AUTOSAR XML (schema 4-2-2)
package /ComponentTypes
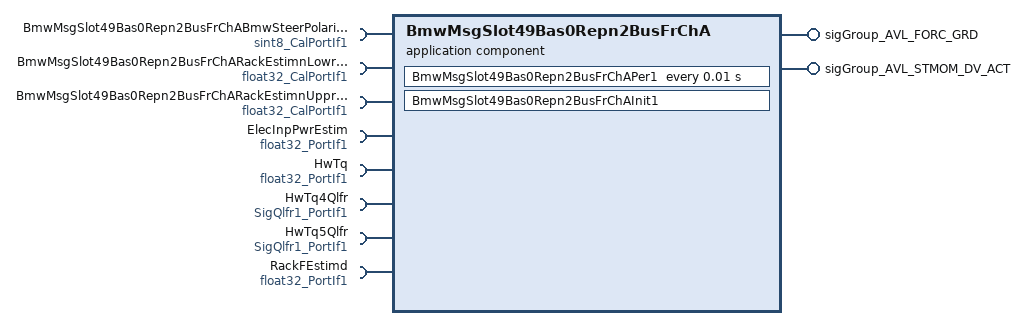
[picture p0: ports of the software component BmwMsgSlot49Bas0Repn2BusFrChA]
  application sw component type BmwMsgSlot49Bas0Repn2BusFrChA
    provide port sigGroup_AVL_FORC_GRD: nonqueued-sender-com-spec{data-element=sigGroup_AVL_FORC_GRD, uses-end-to-end-protection=true, init-value=fields=[AVL_FORC_GRD:0, AVL_PWR_EL_EPS_COOD:120, ALIV_AVL_FORC_GRD:15, CRC_AVL_FORC_GRD:0, QU_AVL_FORC_GRD:8, AVL_FORC_GRD_dummy_12_15:15]}, provided-interface=sigGroup_AVL_FORC_GRD
    provide port sigGroup_AVL_STMOM_DV_ACT: nonqueued-sender-com-spec{data-element=sigGroup_AVL_STMOM_DV_ACT, uses-end-to-end-protection=true, init-value=fields=[AVL_STMOM_DV_ACT:2000, ALIV_AVL_STMOM_DV_ACT:15, QU_AVL_STMOM_DV_ACT:8, CRC_AVL_STMOM_DV_ACT:0, AVL_STMOM_DV_ACT_dummy_12_15:15]}, provided-interface=sigGroup_AVL_STMOM_DV_ACT
    8 x require port:
      BmwMsgSlot49Bas0Repn2BusFrChABmwSteerPolarity: parameter-require-com-spec{init-value=-1, parameter=Val}, required-interface=sint8_CalPortIf1
      BmwMsgSlot49Bas0Repn2BusFrChARackEstimnLowrLim: parameter-require-com-spec{init-value=-25000, parameter=Val}, required-interface=float32_CalPortIf1
      BmwMsgSlot49Bas0Repn2BusFrChARackEstimnUpprLim: parameter-require-com-spec{init-value=25000, parameter=Val}, required-interface=float32_CalPortIf1
      ElecInpPwrEstim: nonqueued-receiver-com-spec{data-element=Val, filter=data-filter-type=ALWAYS, init-value=0}, required-interface=float32_PortIf1
      HwTq: nonqueued-receiver-com-spec{data-element=Val, filter=data-filter-type=ALWAYS, init-value=0}, required-interface=float32_PortIf1
      HwTq4Qlfr: nonqueued-receiver-com-spec{data-element=Val, filter=data-filter-type=ALWAYS, init-value=0}, required-interface=SigQlfr1_PortIf1
      HwTq5Qlfr: nonqueued-receiver-com-spec{data-element=Val, filter=data-filter-type=ALWAYS, init-value=0}, required-interface=SigQlfr1_PortIf1
      RackFEstimd: nonqueued-receiver-com-spec{data-element=Val, filter=data-filter-type=ALWAYS, init-value=0}, required-interface=float32_PortIf1
    behavior BmwMsgSlot49Bas0Repn2BusFrChA_InternalBehavior
      ar-typed-per-instance-memorys:
        data PerCntr: sw-calibration-access=READ-ONLY, type=uint8
      init event BmwMsgSlot49Bas0Repn2BusFrChA_InitEvent: start-on-event=BmwMsgSlot49Bas0Repn2BusFrChAInit1
      timing event TMT_BmwMsgSlot49Bas0Repn2BusFrChA_Per1: start-on-event=BmwMsgSlot49Bas0Repn2BusFrChAPer1, period=0.01
      port-api-options:
        enable-take-address=false, error-handling=NO-TRANSFORMER-ERROR-HANDLING, indirect-api=false, port=BmwMsgSlot49Bas0Repn2BusFrChABmwSteerPolarity
        enable-take-address=false, error-handling=NO-TRANSFORMER-ERROR-HANDLING, indirect-api=false, port=BmwMsgSlot49Bas0Repn2BusFrChARackEstimnLowrLim
        enable-take-address=false, error-handling=NO-TRANSFORMER-ERROR-HANDLING, indirect-api=false, port=BmwMsgSlot49Bas0Repn2BusFrChARackEstimnUpprLim
        enable-take-address=false, error-handling=NO-TRANSFORMER-ERROR-HANDLING, indirect-api=false, port=ElecInpPwrEstim
        enable-take-address=false, error-handling=NO-TRANSFORMER-ERROR-HANDLING, indirect-api=false, port=HwTq
        enable-take-address=false, error-handling=NO-TRANSFORMER-ERROR-HANDLING, indirect-api=false, port=HwTq4Qlfr
        enable-take-address=false, error-handling=NO-TRANSFORMER-ERROR-HANDLING, indirect-api=false, port=HwTq5Qlfr
        enable-take-address=false, error-handling=NO-TRANSFORMER-ERROR-HANDLING, indirect-api=false, port=RackFEstimd
        enable-take-address=false, error-handling=NO-TRANSFORMER-ERROR-HANDLING, indirect-api=false, port=sigGroup_AVL_FORC_GRD
        enable-take-address=false, error-handling=NO-TRANSFORMER-ERROR-HANDLING, indirect-api=false, port=sigGroup_AVL_STMOM_DV_ACT
      runnable BmwMsgSlot49Bas0Repn2BusFrChAInit1
      runnable BmwMsgSlot49Bas0Repn2BusFrChAPer1
        data-receive-point-by-arguments:
          5 x access:
            REC_ElecInpPwrEstim_Val: accessed-variable=ElecInpPwrEstim.Val
            REC_HwTq_Val: accessed-variable=HwTq.Val
            REC_HwTq4Qlfr_Val: accessed-variable=HwTq4Qlfr.Val
            REC_HwTq5Qlfr_Val: accessed-variable=HwTq5Qlfr.Val
            REC_RackFEstimd_Val: accessed-variable=RackFEstimd.Val
        data-send-points:
          access SEND_sigGroup_AVL_FORC_GRD_sigGroup_AVL_FORC_GRD: accessed-variable=sigGroup_AVL_FORC_GRD.sigGroup_AVL_FORC_GRD
          access SEND_sigGroup_AVL_STMOM_DV_ACT_sigGroup_AVL_STMOM_DV_ACT: accessed-variable=sigGroup_AVL_STMOM_DV_ACT.sigGroup_AVL_STMOM_DV_ACT
  swc implementation BmwMsgSlot49Bas0Repn2BusFrChA_Implementation: behavior=BmwMsgSlot49Bas0Repn2BusFrChA_InternalBehavior
    code-descriptors:
      code Default: artifact-descriptors=autosar-engineering-object={short-label=Default, category=SWSRC}
